AUTOSAR XML (schema 4-2-2)
package /Components
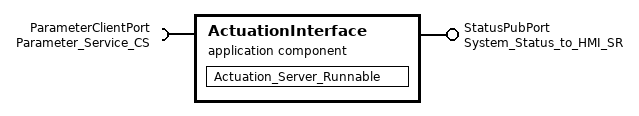
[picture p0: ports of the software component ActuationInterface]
  application sw component type ActuationInterface
    provide port StatusPubPort: provided-interface=System_Status_to_HMI_SR
    provide/require port PlannerServerPort: provided-required-interface=Planner_to_Actuation_CS
    require port ParameterClientPort: required-interface=Parameter_Service_CS
    behavior ActuationInterface_Behavior
      data send completed event CAN_Tx_Completed: start-on-event=Planner_Main_Runnable, event-source=Write_ActuationAck
      operation invoked event Actuation_Command_Invoked: start-on-event=Planner_Main_Runnable, operation=PlannerServerPort.SendControl
      transformer hard error event Actuation_Fault: start-on-event=Planner_Main_Runnable, operation=PlannerServerPort.ReportFault
      runnable Actuation_Server_Runnable: minimum-start-interval=25, symbol=ActuationInterface_Actuation_Server_Runnable
        data-write-access:
          access Write_ActuationAck: accessed-variable=StatusPubPort.ActuationAck
        sync call Planner_Control_CallPoint: operation=PlannerServerPort.SendControl, timeout=100
